# YTM32B1MD2 register map
Vendor: YTMicro; File version: 1.0
CPU: CM33 r0p4, little endian, MPU, FPU, 2 interrupt priority bits
Registers are 32-bit, read-write, reset 0x0 unless marked. A register's access mark holds for its fields unless they carry their own. Offsets are from the block's base; [hi:lo] are bit positions.

## CRC0 — Cyclic Redundancy Check
Base 0x40065000; register names take the prefix CRC0_
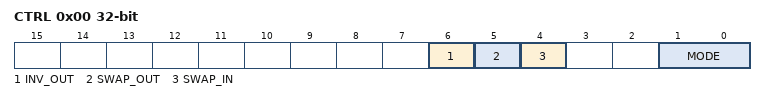
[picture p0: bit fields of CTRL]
0x00 CTRL
  [6] INV_OUT — Bit-inversion for all CRC output bits.
    0=Disable the bit-inversion; 1=Enable the bit-inversion
  [5] SWAP_OUT — Swap all the valid bits (16/32-bit) for CRC output data.
    0=Disable the output bit-swap; 1=Enable the output bit-swap
  [4] SWAP_IN — Enable bit-swap in each byte for CRC input data.
    0=Disable the input bit-swap; 1=Enable the input bit-swap
  [1:0] MODE — Select CRC calculation mode.
    0=Select CRC-4 mode; 1=Select CRC-16 mode; 2=Select CRC-32 mode; 3=Select CRC-8 mode
0x04 INIT
  [31:0] SEED — This register contains the CRC initial seed value.
0x08 IN32 wo
  [31:0] DATA rw — CRC data input in 32 bits
0x0C RESULT ro
  [31:0] RESULT rw — This register contains the result of CRC calculation. In CRC-16 mode, only the low 16 bits are valid. In CRC-4 mode, only the low 4 bits are valid.

## EMU0 — ECC Management Unit
Base 0x40072000; register names take the prefix EMU0_
0x00 EIGCR
  [31:0] GEN — This bit will enable or disable all channels' error injection functions. Write 0x89abcdef will enable this function. Read 0 means, global error injection is disabled Read 1 means, global error injection is enabled
0x04 EICHCR
  [0] CHEN — This field enable or disable channel n error injection function. Enable channel n error injection function should enable this field and EIGCR[GEN]. Any write to EICHDn_ADDR, EICHDn_CHKBIT, EICHDn_DATA register will clear this field. 0b - Channel n error injection is disabled 1b - Channel n error injection is enabled when global error injection is enabled
0x10 EICHD0_ADDR
  [31:0] ADDR — This field defines which memory address will be injected error when read access. when the ADDR is not 0, error will be injected according to this field's value. If ADDR is 0xFFFFFFFF, error will be injected at all read access operation.
0x14 EICHD0_CHKBIT
  [6:0] CHKBIT — This field defines a bit-mapped mask that specifies whether the corresponding bit of the checkbit bus from the target on-chip memory should be inverted or remain unmodified. ewline 0b - The corresponding bit of the checkbit bus remains unmodified. ewline 1b - The corresponding bit of the checkbit bus is inverted. ewline The checkbit can only support injecting error in fixed positions, the mask data is 4.
0x18 EICHD0_DATA
  [31:0] DATA — This field defines a bit-mapped mask that specifies whether the corresponding bit of the read data bus from the target on-chip memory should be inverted or remain unmodified. ewline 0b - The corresponding bit of the databit bus remains unmodified. ewline 1b - The corresponding bit of the databit bus is inverted. ewline The databit can only support injecting error in fixed positions, the mask data is 2.
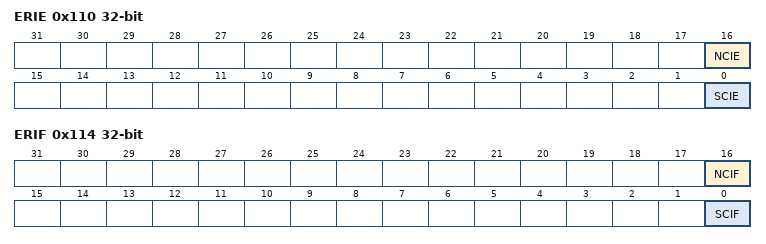
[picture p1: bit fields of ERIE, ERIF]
0x110 ERIE
  [16] NCIE — Non-Correctable error interrupt enable. 0b - Channel n Non-Correctable Error interrupt is disabled 1b - Channel n Non-Correctable Error interrupt is enabled
  [0] SCIE — Single correctable error interrupt enable 0b - Channel n Single Correctable Error interrupt is disabled 1b - Channel n Single Correctable Error interrupt is enabled
0x114 ERIF — This register is reset by Power-on Reset.
  [16] NCIF — Non-Correctable error interrupt flag. NCIF flag is kept when software reset but cleared when POR. 0b - Channel n Non-Correctable Error interrupt not detected 1b - Channel n Non-Correctable Error interrupt detected
  [0] SCIF — Single Correctable error interrupt flag. SCIF flag is kept when software reset but cleared when POR. 0b - Channel n Single Correctable Error interrupt not detected 1b - Channel n Single Correctable Error interrupt detected
0x118 ERINFO0_ADDR ro — This register is reset by Power-on Reset.
  [31:0] ADDR — This field contains the faulting system address of the last recorded ECC event on on-chip memories.
0x11C ERINFO0_SYND ro — This register is reset by Power-on Reset.
  [6:0] SYNDROME — This field contains the syndrome of the last recorded ECC event on on-chip memories.
0x120 ERINFO0_CNT — This register is reset by Power-on Reset.
  [7:0] CNT — For each correctable error event, the EMU increments this field's error count value until the counter reaches its maximum value 0xFF. CNT will not change once it reaches 0xFF and will not wrap even if error occurs. Read this field to determine the correctable error count value so far. Write zero to this field to reset the counter. Writing non-zero (or partial zero) values has no effect.
